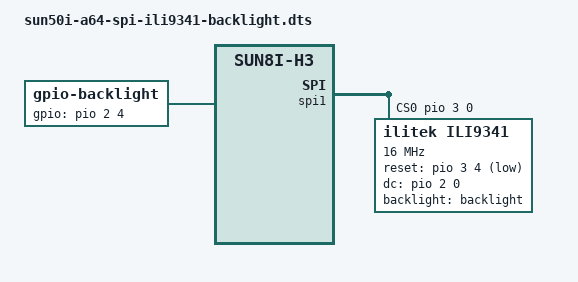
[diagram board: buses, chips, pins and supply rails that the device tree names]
/*
* DevDotNet.ORG <anton@devdotnet.org>
*
* MIT License
* 
* Device: 2.4inch SPI Module ILI9341 for banana pi m-64 with Control backlight gpio-backlight (on/off)
* Module      Connector
* CS		<-  PD0
* RESET		<-  PD4
* DC/RS		<-  PC0
* SDI(MOSI)	<-  PD2
* SCK		<-  PD1
* LED		<-  PC4 
* SDO(MISO)	->  PD3
*
* on/off LCD echo "0/1" > /sys/class/backlight/backlight/brightness
*/
/dts-v1/;
/plugin/;

/ {
	compatible = "allwinner,sun8i-h3";	

  fragment@0 {
    target = <&pio>;
    __overlay__ {
      backlight_pin: backlight_pin {
        pins = "PC4"; 
        function = "gpio_out";
      };
    };
  };
  
  fragment@1 {
    target-path = "/";
    __overlay__ {
      backlight: backlight {
        compatible = "gpio-backlight";
        pinctrl-names = "default";
        pinctrl-0 = <&backlight_pin>;
        gpios = <&pio 2 4 0>; //PIN27 GPIO68 PC4
        default-on;
      };            
    };
  };

  fragment@2 {
    target = <&pio>;
    __overlay__ {
      ili9341_pins: ili9341_pins {
        pins = "PD4", "PC0"; /*RESET, DC_RS*/
        function = "gpio_out", "gpio_out" ;
      };
    };
  };
  
  fragment@3 {
    target = <&spi1>;
    __overlay__ {
      status = "okay";      
      cs-gpios = <&pio 3 0 0>; /* PD0 */

      ili9341: ili9341@0 {
        compatible = "ilitek,ili9341";
        reg = <0>;
        pinctrl-names = "default";
        pinctrl-0 = <&ili9341_pins>;
        spi-max-frequency = <16000000>;
        rotate = <90>;
        bgr;
        fps = <25>;
        buswidth = <8>;
        reset-gpios = <&pio 3 4 1>; /*RESET=PD4*/
        dc-gpios = <&pio 2 0 0>; /*DC_RS=PC0*/
        backlight = <&backlight>;
        /*led-gpios = <&pio 2 4 0>; LED=PC4*/
        debug = <0>;
      };
    };
  };
};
